# R7KA8D2AD register map
Vendor: Renesas Electronics Corporation; Series: RA8; File version: 1.10.02
CPU: CM85 r0p2, little endian, MPU, FPU, VTOR, 4 interrupt priority bits, 96 interrupts
Registers are 32-bit, read-write, reset 0x0 unless marked. A register's access mark holds for its fields unless they carry their own. Offsets are from the block's base; [hi:lo] are bit positions; {n}, {i} and the like mark numbered series; 'fields as' and 'values as' point back to an identical list.

## GLCDC
Base 0x40342000
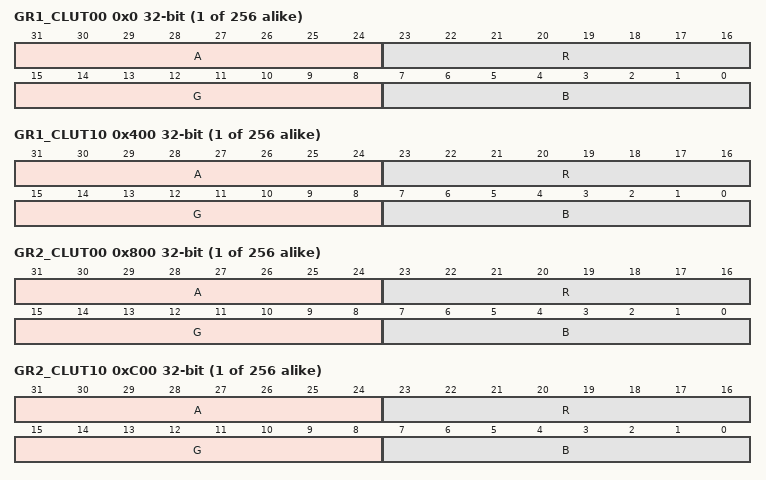
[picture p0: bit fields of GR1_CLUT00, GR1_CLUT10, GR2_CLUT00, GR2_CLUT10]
{0x0+4i} GR1_CLUT0{i} (i=0..255) — Color Palette
  [31:24] A — Alpha blending value of color palette n plane for graphics m plane. Unsigned 8-bit integer.
  [23:16] R — R value of color palette n plane for graphics m plane. Unsigned 8-bit integer.
  [15:8] G — G value of color palette n plane for graphics m plane. Unsigned 8-bit integer.
  [7:0] B — B value of color palette n plane for graphics m plane. Unsigned 8-bit integer.
{0x400+4i} GR1_CLUT1{i} (i=0..255) — Color Palette
  fields as GR1_CLUT00
{0x800+4i} GR2_CLUT0{i} (i=0..255) — Color Palette
  fields as GR1_CLUT00
{0xC00+4i} GR2_CLUT1{i} (i=0..255) — Color Palette
  fields as GR1_CLUT00
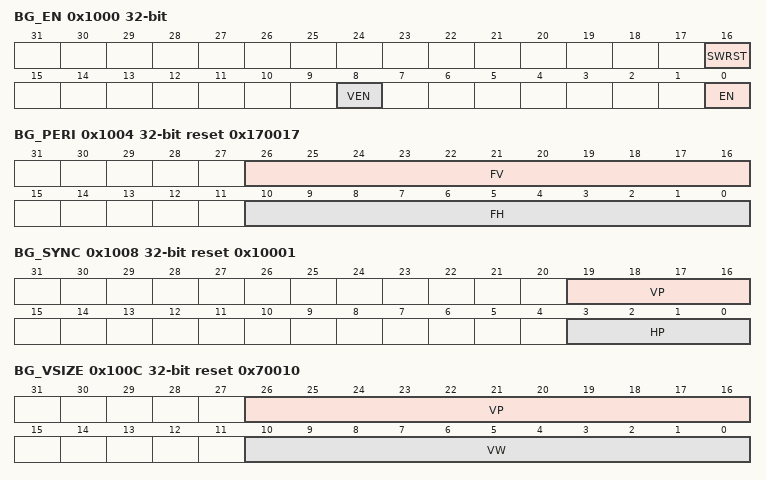
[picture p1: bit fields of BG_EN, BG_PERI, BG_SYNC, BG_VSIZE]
0x1000 BG_EN — Background Plane Setting Operation Control Register
  [16] SWRST — Software Reset Control
    0=Place entire module in software reset state; 1=Release entire module from software reset state
  [8] VEN — Control of GLCDC Internal Register Value Reflection to Internal Operations
    0=Disable GLCDC register values from being reflected in internal operations at start of screen generation; 1=Enable GLCDC register values to be reflected in internal operations at start of screen generation
  [0] EN — Background Plane Operation Enable
    0=Disable background plane operation; 1=Enable background plane operation
0x1004 BG_PERI reset 0x170017 — Background Plane Setting Free-Running Period Register
  [26:16] FV — Background Plane Vertical Synchronization Signal Period
    19=20 lines; 0x3FF=1024 lines; 0x7FF=2048 lines
  [10:0] FH — Background Plane Horizontal Synchronization Signal Period
    23=24 cycles (pixels); 0x3FF=1024 cycles (pixels); 0x7FF=2048 cycles (pixels)
0x1008 BG_SYNC reset 0x10001 — Background Plane Setting Synchronization Position Register
  [19:16] VP — Background Plane Vertical Synchronization Assertion Position
    0=Setting prohibited; other=Others (VPth line)
  [3:0] HP — Background Plane Horizontal Synchronization Signal Assertion Position
    0=Setting prohibited; other=Others (HPth cycle (pixel))
0x100C BG_VSIZE reset 0x70010 — Background Plane Setting Full Image Vertical Size Register
  [26:16] VP — Background Plane Vertical Valid Pixel Start Position
  [10:0] VW — Background Plane Vertical Valid Pixel Width
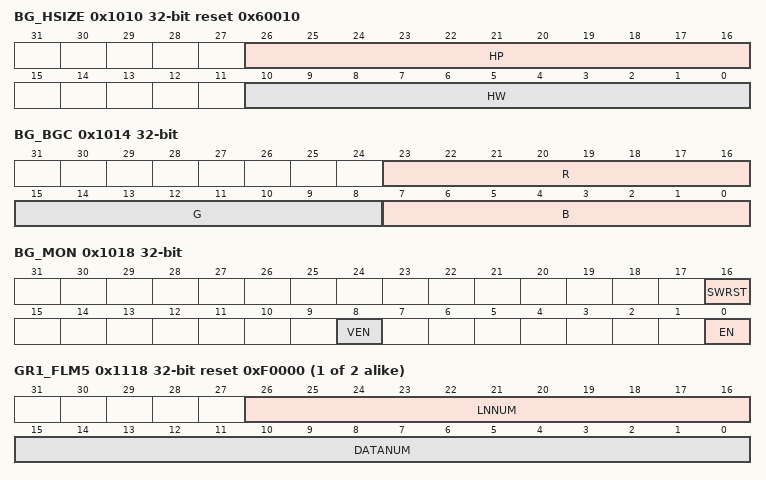
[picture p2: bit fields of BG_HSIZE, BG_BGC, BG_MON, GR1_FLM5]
0x1010 BG_HSIZE reset 0x60010 — Background Plane Setting Full Image Horizontal Size Register
  [26:16] HP — Background Plane Horizontal Valid Pixel Start Position
  [10:0] HW — Background Plane Horizontal Valid Pixel Width
0x1014 BG_BGC — Background Plane Setting Background Color Register
  [23:16] R — Background Plane Valid Pixel Area R Value
  [15:8] G — Background Plane Valid Pixel Area G Value
  [7:0] B — Background Plane Valid Pixel Area B Value
0x1018 BG_MON ro — Background Plane Setting Status Monitor Register
  [16] SWRST — Entire Module SW Reset State Monitor
    0=Entire module is in software reset state; 1=Entire module is released from software reset state
  [8] VEN — Entire Module Internal Operation Reflection Control Signal Monitor
    0=Signal for controlling reflection of the register values to internal operations on assertion of vertical synchronization signal is negated; 1=Signal for controlling reflection of the register values to internal operations on assertion of vertical synchronization signal is asserted
  [0] EN — Background Plane Operation Monitor
    0=Operation is stopped; 1=Operation is in progress
{0x1000+0x100*i} GR{i}_VEN (i=1..2) — Graphics {i} Register Update Control Register
  [0] PVEN — This bit is cleared to 0 by an internal source.
    0=Disable reflection of register values to internal operations on assertion of vertical synchronization signal (VS); 1=Enable reflection of register values to internal operations on assertion of the vertical synchronization signal (VS)
{0x1004+0x100*i} GR{i}_FLMRD (i=1..2) — Graphics {i} Frame Buffer Read Control Register
  [0] RENB — Graphics Data Read Enable
    0=Disable reading; 1=Enable reading
{0x1008+0x100*i} GR{i}_FLM1 (i=1..2) reset 0x3 — Graphics {i} Frame Buffer Control Register 1
  [1:0] BSTMD — Burst Transfer Control for Graphics Data Access
    3=16-beat increment burst transfer (64-byte boundary); other=Others (Setting prohibited)
{0x100C+0x100*i} GR{i}_FLM2 (i=1..2) — Graphics {i} Frame Buffer Control Register 2
  [31:0] BASE — Base Address for Accessing Graphics Data
{0x1010+0x100*i} GR{i}_FLM3 (i=1..2) — Graphics {i} Frame Buffer Control Register 3
  [31:16] LNOFF — Macro Line Offset Address for Accessing Graphics Data
{0x1018+0x100*i} GR{i}_FLM5 (i=1..2) reset 0xF0000 — Graphics {i} Frame Buffer Control Register 5
  [26:16] LNNUM — Number of Lines Per Frame for Accessing Graphics Data
  [15:0] DATANUM — Number of Data Transfer Times Per Line for Accessing Graphics Data
{0x101C+0x100*i} GR{i}_FLM6 (i=1..2) — Graphics {i} Frame Buffer Control Register 6
  [30:28] FORMAT — Data Format for Accessing Graphics Data
    0=RGB565 (16 bits/pixel); 1=RGB888 (32 bits/pixel, 8 bits on the MSB side are invalid); 2=ARGB1555 (16 bits/pixel, 1 bit of A is LUT data); 3=ARGB4444 (16 bits/pixel); 4=ARGB8888 (32 bits/pixel); 5=CLUT8 (8 bits/pixel); 6=CLUT4 (4 bits/pixel); 7=CLUT1 (1 bit/pixel)
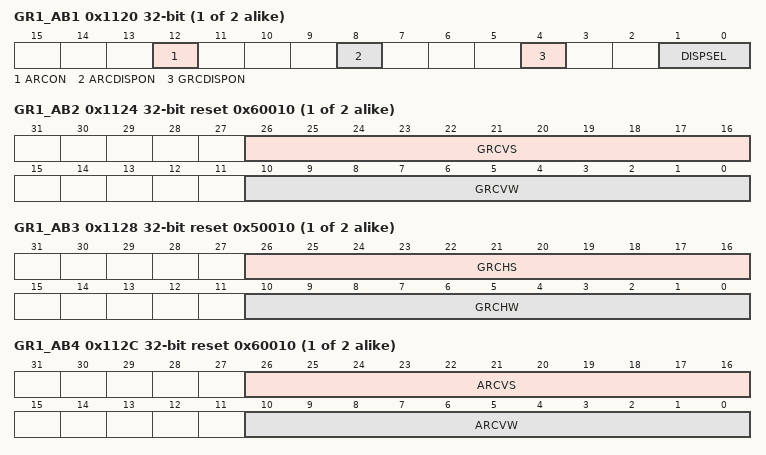
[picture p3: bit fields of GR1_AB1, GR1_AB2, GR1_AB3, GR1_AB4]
{0x1020+0x100*i} GR{i}_AB1 (i=1..2) — Graphics {i} Alpha Blending Control Register 1
  [12] ARCON — Rectangular Area Alpha Blending Control
    0=Turn blending off; 1=Turn blending on
  [8] ARCDISPON — Image Area Border Display Control for Rectangular Area Alpha Blending
    0=Turn display off; 1=Turn display on
  [4] GRCDISPON — Graphics Image Area Border Display Control
    0=Turn display off; 1=Turn display on
  [1:0] DISPSEL — Graphics Display Plane Control
    0=Background color display (value set in the GRn_BASE register); 1=Lower-layer graphics display; 2=Current graphics display; 3=Blended display of lower-layer graphics (input image from the previous stage) and current graphics (data read from the GLCDC0 and GLCDC1 bus)
{0x1024+0x100*i} GR{i}_AB2 (i=1..2) reset 0x60010 — Graphics {i} Alpha Blending Control Register 2
  [26:16] GRCVS — Vertical Start Position of Graphics Image Area
  [10:0] GRCVW — Vertical Width of Graphics Image Area
{0x1028+0x100*i} GR{i}_AB3 (i=1..2) reset 0x50010 — Graphics {i} Alpha Blending Control Register 3
  [26:16] GRCHS — Horizontal Start Position of Graphics Image Area
  [10:0] GRCHW — Horizontal Width of Graphics Image Area
{0x102C+0x100*i} GR{i}_AB4 (i=1..2) reset 0x60010 — Graphics {i} Alpha Blending Control Register 4
  [26:16] ARCVS — Vertical Start Position of Rectangular Area Alpha Blending Image Area
  [10:0] ARCVW — Vertical Width of Rectangular Area Alpha Blending Image Area
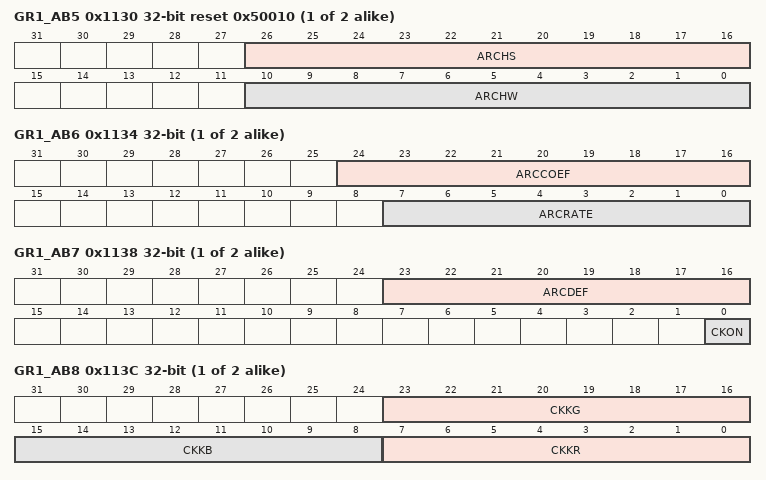
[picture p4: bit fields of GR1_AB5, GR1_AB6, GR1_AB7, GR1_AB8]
{0x1030+0x100*i} GR{i}_AB5 (i=1..2) reset 0x50010 — Graphics {i} Alpha Blending Control Register 5
  [26:16] ARCHS — Horizontal Start Position of Rectangular Area Alpha Blending Image Area
  [10:0] ARCHW — Horizontal Width of Rectangular Area Alpha Blending Image Area
{0x1034+0x100*i} GR{i}_AB6 (i=1..2) — Graphics {i} Alpha Blending Control Register 6
  [24:16] ARCCOEF — Alpha Coefficient for Alpha Blending in Rectangular Area
  [7:0] ARCRATE — Frame Rate for Alpha Blending in Rectangular Area
{0x1038+0x100*i} GR{i}_AB7 (i=1..2) — Graphics {i} Alpha Blending Control Register 7
  [23:16] ARCDEF — Initial Alpha Value for Alpha Blending in Rectangular Area
  [0] CKON — RGB-Index Chroma-Key Processing Control
    0=Disable chroma-key processing; 1=Enable chroma-key processing
{0x103C+0x100*i} GR{i}_AB8 (i=1..2) — Graphics {i} Alpha Blending Control Register 8
  [23:16] CKKG — G Signal for RGB-Index Chroma-Key Processing
  [15:8] CKKB — B Signal for RGB-Index Chroma-Key Processing
  [7:0] CKKR — R Signal for RGB-Index Chroma-Key Processing
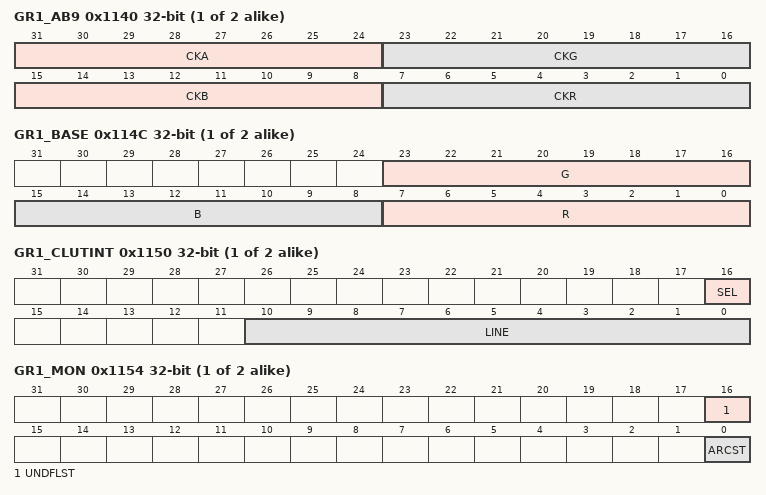
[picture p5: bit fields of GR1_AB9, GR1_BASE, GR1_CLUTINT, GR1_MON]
{0x1040+0x100*i} GR{i}_AB9 (i=1..2) — Graphics {i} Alpha Blending Control Register 9
  [31:24] CKA — A Value after RGB-Index Chroma-Key Processing Replacement
  [23:16] CKG — G Value after RGB-Index Chroma-Key Processing Replacement
  [15:8] CKB — B Value after RGB-Index Chroma-Key Processing Replacement
  [7:0] CKR — R Value after RGB-Index Chroma-Key Processing Replacement
{0x104C+0x100*i} GR{i}_BASE (i=1..2) — Graphics {i} Background Color Control Register
  [23:16] G — Background Color G Value
  [15:8] B — Background Color B Value
  [7:0] R — Background Color R Value
{0x1050+0x100*i} GR{i}_CLUTINT (i=1..2) — Graphics {i} CLUT Table Interrupt Control Register
  [16] SEL — CLUT Table Control
    0=Select CLUT table 0; 1=Select CLUT table 1
  [10:0] LINE — Number of Detection Lines
{0x1054+0x100*i} GR{i}_MON (i=1..2) ro — Graphics {i} Status Monitor Register
  [16] UNDFLST — Underflow Status Monitor
    0=No underflow occurred in internal operations; 1=Underflow occurred in internal operations
  [0] ARCST — Status Monitor for Alpha Blending in Rectangular Area
    0=Fade-in/fade-out not in progress; 1=Fade-in/fade-out in progress
0x1300 GAMG_LATCH — Gamma G Register Update Control Register
  [0] VEN — Control of Gamma Correction × Module Register Value Reflection to Internal Operations
    values as GR1_VEN.PVEN
0x1304 GAM_SW — Gamma Correction Block Function Switch Register
  [0] GAMON — Gamma Correction On/Off Control
    0=Turn off gamma correction; 1=Turn on gamma correction
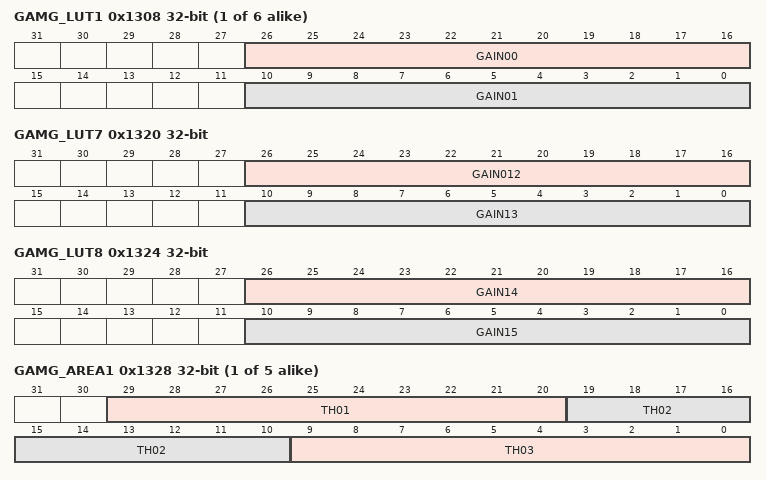
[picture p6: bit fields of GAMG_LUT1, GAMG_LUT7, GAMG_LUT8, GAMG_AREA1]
{0x1304+4i} GAMG_LUT{i} (i=1..6) — Gamma G Correction Block Table Setting Register {i}
  [26:16] GAIN{2i-2:02} — Gain Value of Area {2i-2}
  [10:0] GAIN{2i-1:02} — Gain Value of Area {2i-1}
0x1320 GAMG_LUT7 — Gamma G Correction Block Table Setting Register 7
  [26:16] GAIN012 — Gain Value of Area 12
  [10:0] GAIN13 — Gain Value of Area 13
0x1324 GAMG_LUT8 — Gamma G Correction Block Table Setting Register 8
  [26:16] GAIN14 — Gain Value of Area 14
  [10:0] GAIN15 — Gain Value of Area 15
{0x1324+4i} GAMG_AREA{i} (i=1..5) — Gamma G Correction Block Area Setting Register {i}
  [29:20] TH{3i-2:02} — Start Threshold of Area {3i-2}
  [19:10] TH{3i-1:02} — Start Threshold of Area {3i-1}
  [9:0] TH{3i:02} — Start Threshold of Area {3i}
0x1340 GAMB_LATCH — Gamma B Register Update Control Register
  fields as GAMG_LATCH
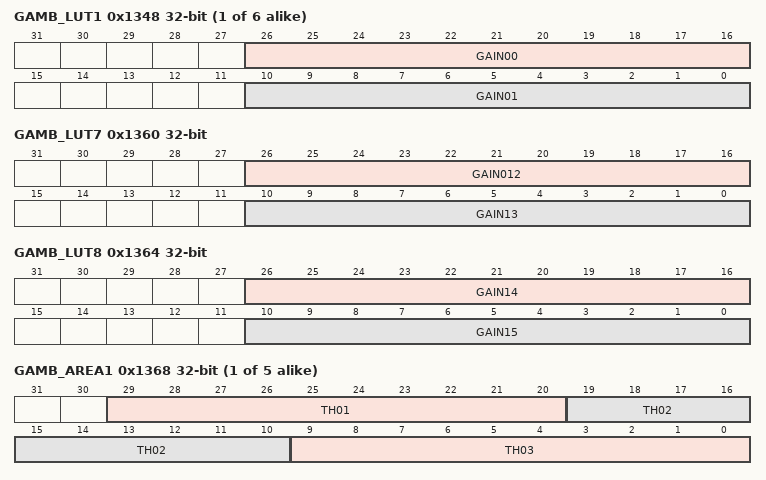
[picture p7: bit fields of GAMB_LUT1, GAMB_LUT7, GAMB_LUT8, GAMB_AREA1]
{0x1344+4i} GAMB_LUT{i} (i=1..6) — Gamma B Correction Block Table Setting Register {i}
  fields as GAMG_LUT1
0x1360 GAMB_LUT7 — Gamma B Correction Block Table Setting Register 7
  fields as GAMG_LUT7
0x1364 GAMB_LUT8 — Gamma B Correction Block Table Setting Register 8
  fields as GAMG_LUT8
{0x1364+4i} GAMB_AREA{i} (i=1..5) — Gamma B Correction Block Area Setting Register {i}
  fields as GAMG_AREA1
0x1380 GAMR_LATCH — Gamma R Register Update Control Register
  fields as GAMG_LATCH
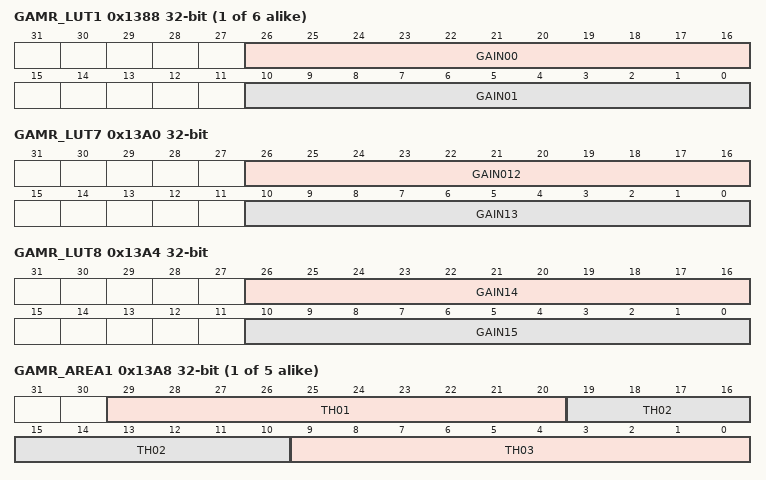
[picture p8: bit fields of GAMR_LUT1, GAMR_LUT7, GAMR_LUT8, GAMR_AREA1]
{0x1384+4i} GAMR_LUT{i} (i=1..6) — Gamma R Correction Block Table Setting Register {i}
  fields as GAMG_LUT1
0x13A0 GAMR_LUT7 — Gamma R Correction Block Table Setting Register 7
  fields as GAMG_LUT7
0x13A4 GAMR_LUT8 — Gamma R Correction Block Table Setting Register 8
  fields as GAMG_LUT8
{0x13A4+4i} GAMR_AREA{i} (i=1..5) — Gamma R Correction Block Area Setting Register {i}
  fields as GAMG_AREA1
0x13C0 OUT_VLATCH — Output Control Block Register Update Control Register
  [0] VEN — Control of Output Control Module Register Value Reflection to Internal Operations
    0=Disable reflection of register values to internal operations on assertion of vertical synchronization signal (VS); 1=Enable reflection of register values to internal operations on assertion of vertical synchronization signal (VS)
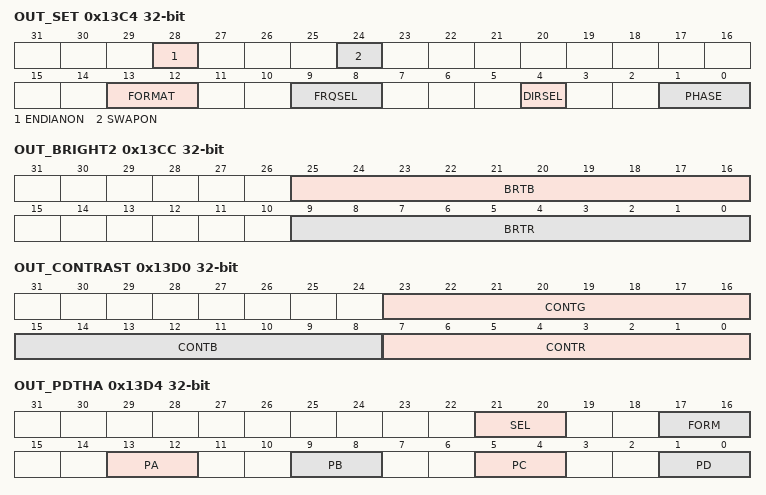
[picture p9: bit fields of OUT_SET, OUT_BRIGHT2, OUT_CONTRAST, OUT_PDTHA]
0x13C4 OUT_SET — Output Control Block Output Interface Register
  [28] ENDIANON — Bit Endian Control
    0=Descending order (little endian); 1=Ascending order (big endian)
  [24] SWAPON — Pixel Order Control
    0=RGB order; 1=BGR order
  [13:12] FORMAT — Output Format Select
    0=RGB888 — select RGB888 as dither output format; 1=RGB666 — select RGB666 as dither output format; 2=RGB565 — select RGB565 as dither output format; 3=Serial RGB — select RGB888 as dither output format. Select dither output format in OUT_PDTHA.FORM[1:0]
  [9:8] FRQSEL — Clock Frequency Division Control
    0=No frequency division, parallel RGB; 1=Setting prohibited; 2=Quarter frequency (serial RGB); 3=Setting prohibited
  [4] DIRSEL — Scan Direction Select of Serial RGB Format
    0=Forward scan; 1=Reverse scan
  [1:0] PHASE — Data Output Delay Control in Serial RGB Format
    0=0 cycle; 1=1 cycle; 2=2 cycles; 3=3 cycles
0x13C8 OUT_BRIGHT1 — Output Control Block Brightness Correction Register 1
  [9:0] BRTG — Brightness Adjustment of G Signal
0x13CC OUT_BRIGHT2 — Output Control Block Brightness Correction Register 2
  [25:16] BRTB — Brightness Adjustment of B Signal
  [9:0] BRTR — Brightness Adjustment of R Signal
0x13D0 OUT_CONTRAST — Output Control Block Contrast Correction Register
  [23:16] CONTG — Contrast Adjustment of G Signal
  [15:8] CONTB — Contrast Adjustment of B Signal
  [7:0] CONTR — Contrast Adjustment of R Signal
0x13D4 OUT_PDTHA — Output Control Block Panel Dither Correction Register
  [21:20] SEL — Operation Mode
    0=Truncate; 1=Round-off; 2=2×2 pattern dither; 3=Setting prohibited
  [17:16] FORM — Output Format Select
    0=RGB888; select RGB888 or serial RGB as output interface format; 1=RGB666; select RGB666 as output interface format; 2=RGB565; select RGB565 as output interface format; 3=Setting prohibited Select output interface format in OUT_SET.FORMAT[1:0]
  [13:12] PA — Pattern Value (A) of 2×2 Pattern Dither
  [9:8] PB — Pattern Value (B) of 2×2 Pattern Dither
  [5:4] PC — Pattern Value (C) of 2×2 Pattern Dither
  [1:0] PD — Pattern Value (D) of 2×2 Pattern Dither
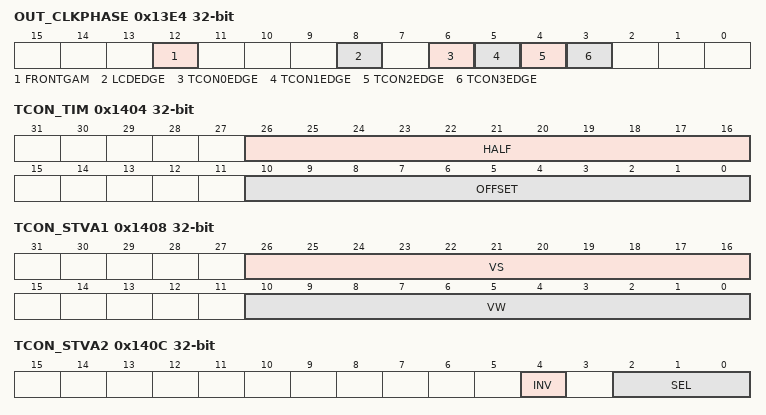
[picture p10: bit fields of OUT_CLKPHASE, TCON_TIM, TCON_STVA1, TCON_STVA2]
0x13E4 OUT_CLKPHASE — Output Control Block Output Phase Control Register
  [12] FRONTGAM — Correction Control
    0=Process brightness/contrast correction followed by gamma correction; 1=Process gamma correction followed by brightness/contrast correction
  [8] LCDEDGE — LCD_DATA Output Phase Control
    0=Synchronize output with rising edge of LCD_CLK; 1=Synchronize output with falling edge of LCD_CLK
  [6-n] TCON{n}EDGE (n=0..3) — LCD_TCON{n} Output Phase Control
    values as LCDEDGE
0x1404 TCON_TIM — TCON Reference Timing Setting Register
  [26:16] HALF — Vertical Synchronization Signal Generation Change Timing
  [10:0] OFFSET — Horizontal Synchronization Signal Generation Reference Timing
0x1408 TCON_STVA1 — TCON Vertical Timing Setting Register x1
  [26:16] VS — Vertical Synchronization Signal STVx1 First Change Timing
  [10:0] VW — Vertical Synchronization Signal STVx1 Second Change Timing
0x140C TCON_STVA2 — TCON Vertical Timing Setting Register x2
  [4] INV — Vertical Synchronization Signal STVx Polarity Inversion Control
    0=Do not invert; 1=Invert
  [2:0] SEL — Output Signal Select Control for VSOUT/VEOUT Pin
    0=STVA; 1=STVB; 2=STHA; 3=STHB; 4=Setting prohibited; 5=Setting prohibited; 6=Setting prohibited; 7=DE
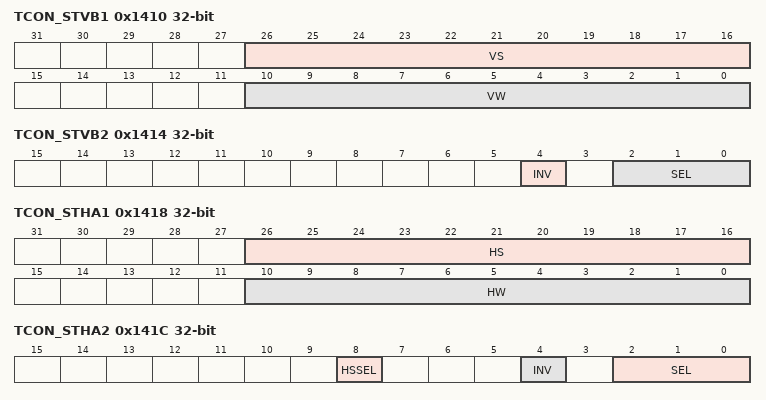
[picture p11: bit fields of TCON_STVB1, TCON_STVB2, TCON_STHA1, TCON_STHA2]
0x1410 TCON_STVB1 — TCON Vertical Timing Setting Register x1
  fields as TCON_STVA1
0x1414 TCON_STVB2 — TCON Vertical Timing Setting Register x2
  fields as TCON_STVA2
0x1418 TCON_STHA1 — TCON Horizontal Timing Setting Register x1
  [26:16] HS — Horizontal Synchronization Signal STHx1 First Change Timing
  [10:0] HW — Horizontal Synchronization Signal STHx1 Second Change Timing
0x141C TCON_STHA2 — TCON Horizontal Timing Setting Register x2
  [8] HSSEL — Horizontal Synchronization Signal STHx Reference Timing Control
    0=Select input horizontal synchronization signal (HSIN) as reference for signal generation; 1=Select offset specified in TCON_TIM.OFFSET[10:0] (horizontal synchronization generation reference timing) as reference for signal generation
  [4] INV — Horizontal Synchronization Signal STHx Polarity Inversion Control
    0=Do not invert; 1=Invert
  [2:0] SEL — Output Signal Select Control for LCD_TCON2/LCD_TCON3 Pin
    values as TCON_STVA2.SEL
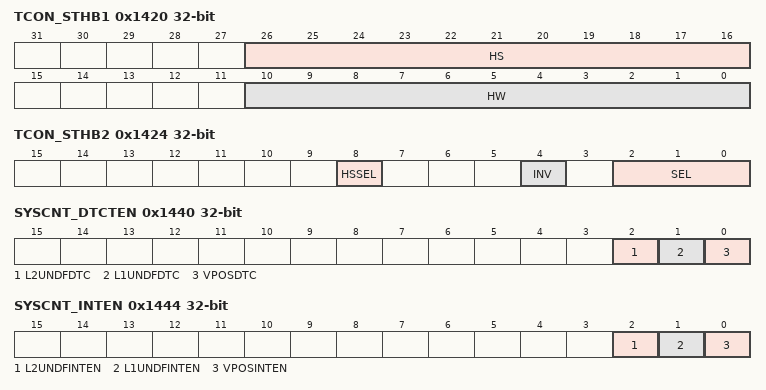
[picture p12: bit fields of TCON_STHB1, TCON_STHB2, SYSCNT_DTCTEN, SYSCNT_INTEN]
0x1420 TCON_STHB1 — TCON Horizontal Timing Setting Register x1
  fields as TCON_STHA1
0x1424 TCON_STHB2 — TCON Horizontal Timing Setting Register x2
  fields as TCON_STHA2
0x1428 TCON_DE — TCON Data Enable Polarity Setting Register
  [0] INV — Data Enable Signal DE Polarity Inversion Control
    0=Do not invert; 1=Invert
0x1440 SYSCNT_DTCTEN — System Control Block State Detection Control Register
  [2] L2UNDFDTC — Graphics 2 Underflow Detection Control
    0=Disable detection of graphics 2 underflow; 1=Enable detection of graphics 2 underflow
  [1] L1UNDFDTC — Graphics 1 Underflow Detection Control
    0=Disable detection of graphics 1 underflow; 1=Enable detection of graphics 1 underflow
  [0] VPOSDTC — Specified Line Detection Control
    0=Disable detection of specified line; 1=Enable detection of specified line
0x1444 SYSCNT_INTEN — System Control Block Interrupt Request Enable Control Register
  [2] L2UNDFINTEN — Interrupt Request Signal GLCDC_L2UNDF Enable Control
    0=Disable GLCDC_L2UNDF output; 1=Enable GLCDC_L2UNDF output
  [1] L1UNDFINTEN — Interrupt Request Signal GLCDC_L1UNDF Enable Control
    0=Disable GLCDC_L1UNDF output; 1=Enable GLCDC_L1UNDF output
  [0] VPOSINTEN — Interrupt Request Signal GLCDC_VPOS Enable Control
    0=Disable GLCDC_VPOS output; 1=Enable GLCDC_VPOS output
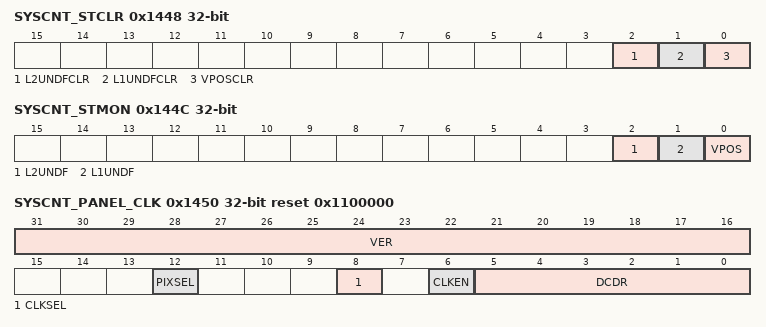
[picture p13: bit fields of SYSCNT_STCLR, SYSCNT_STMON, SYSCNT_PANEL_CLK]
0x1448 SYSCNT_STCLR — System Control Block Status Clear Register
  [2] L2UNDFCLR — Graphics 2 Underflow Detection Flag Clear
    0=No operation; 1=Clears the graphics 2 underflow detection flag
  [1] L1UNDFCLR — Graphics 1 Underflow Detection Flag Clear
    0=No operation; 1=Clear the graphics 1 underflow detection flag
  [0] VPOSCLR — Graphics 2 Specified Line Detection Flag Clear
    0=No operation; 1=Clear the graphics 2 specified line detection flag
0x144C SYSCNT_STMON ro — System Control Block Status Monitor Register
  [2] L2UNDF — Graphics 2 Underflow Detection Flag
    0=No underflow detected in graphics 2; 1=Underflow detected in graphics 2
  [1] L1UNDF — Graphics 1 Underflow Detection Flag
    0=No underflow detected in graphics 1; 1=Underflow detected in graphics 1
  [0] VPOS — Graphics 2 Specified Line Detection Flag
    0=Specified line notification not detected in graphics 2; 1=Specified line notification detected in graphics 2
0x1450 SYSCNT_PANEL_CLK reset 0x1100000 — System Control Block Version and Panel Clock Control Register
  [31:16] VER ro — Version Information
  [12] PIXSEL — Pixel Clock Select Control
    0=Select no frequency division, parallel RGB; 1=Select quarter frequency, serial RGB This setting must have the same value as OUT_SET.FRQSEL[1]
  [8] CLKSEL — Panel Clock Supply Source Control
    0=Select external clock (LCD_EXTCLK); 1=Select LCDCLK
  [6] CLKEN — Panel Clock Output Enable Control
    0=Disable panel clock output; 1=Enable panel clock output Before changing the PIXSEL, CLKSEL, or DCDR bit, this bit must be set to 0
  [5:0] DCDR — Clock Division Ratio Setting Control

## GLCDC_NS
Base 0x50342000
Registers as GLCDC, without GR1_CLUT0*, GR1_CLUT1*, GR2_CLUT0*, GR2_CLUT1*; these are added or differ:
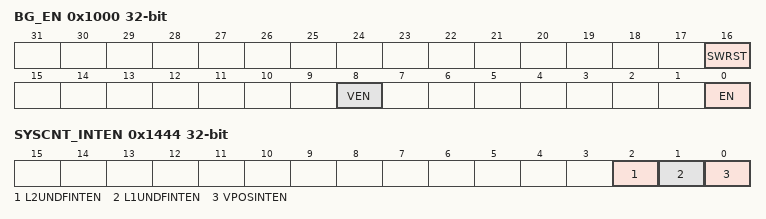
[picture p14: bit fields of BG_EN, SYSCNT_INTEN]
0x1000 BG_EN — Background Plane Setting Operation Control Register
  fields as GLCDC.BG_EN
0x1444 SYSCNT_INTEN — System Control Block Interrupt Request Enable Control Register
  fields as GLCDC.SYSCNT_INTEN
